# cslr_wdt register map
Vendor: Texas Instruments
Peripheral module from a debugger description file (folder C5517).
Address unit: 16 bits
Registers are 16-bit, read-write, reset 0x0 unless marked. A register's access mark holds for its fields unless they carry their own. Offsets are as the file gives them; lines under a group give offsets from that group; [hi:lo] are bit positions; {n}, {i} and the like mark numbered series; 'fields as' and 'values as' point back to an identical list; <NAME> marks a mode.

## WDT — The WDT controller is used to setup the internal timers. Each timer can be configured as a Watchdog or a General purpose timer.
0x00 WDKCKLK — unlocks the WD Kick Register
  [15:0] KICKLOK — Used to unlock the Watchdog Kick Register. A 2 word key sequence must be written to this register. The following keys must be written this order Key 1 = 0x5555 and Key 2 = 0xAAAA. When this is written the Kick register can now be started. When reading back the KICKLOK register, the value that is returned in bits [1:0] give the current state of the lock state machine where 00 = Waiting for Key 1; 01 = Waiting for key 2; 11 = unlocked.
0x02 WDKICK — resets the counter to the start value
  [15:0] KICK — A write to the kick register when it is unlocked causes the the watchdown counter to be reloaded with the value in the WD Start Value register and start counting down again. It does not matter what value is written. Reading the register returns the current value of the counter.
0x04 WDSVLR — unlocks the WD Start value register
  [15:0] STVALLOK — Used to unlock the Watchdog Start Value Register. A 2 word key sequence must be written to this register. The following keys must be written this order Key 1 = 0x6666 and Key 2 = 0xBBBB. When this is written the WD Start Value register can now be input. When reading back the STVALLOK register, the value that is returned in bits [1:0] give the current state of the lock state machine where 00 = Waiting for Key 1; 01 = Waiting for key 2; 11 = unlocked.
0x06 WDSVR — defines the start value for the WD counter
  [15:0] STRTVAL — The value written to this register is what is loaded into the WD counter when the kick register is written to. A read of this register will return the the Start Value for the counter.
0x08 WDENLOK — unlocks the WD enable register
  [15:0] ENLOK — Used to unlock the Watchdog Enable Register. A 3 word key sequence must be written to this register. The following keys must be written this order Key 1 = 0x7777, Key 2 = 0xCCCC, and Key 3 = 0xDDDD. When this is written the WD Enable register can now be input. When reading back the ENLOK register, the value that is returned in bits [1:0] give the current state of the lock state machine where 00 = Waiting for Key 1; 01 = Waiting for key 2; 10 = Waiting for Key 3; 11 = unlocked.
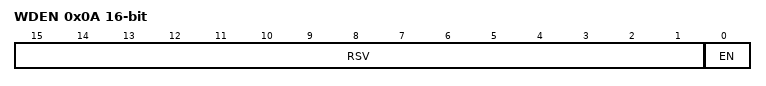
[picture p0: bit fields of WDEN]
0x0A WDEN — WD Enable/disable bit
  [15:1] RSV — Reserved
  [0] EN — used to enable/disable the WD timer. When enabled the counter begins counting down if the counter is allowed to reach 0 the chip will be reset.
    0=DISABLE (Watchdog Timer is disabled); 1=ENABLE (Watchdog Timer is enabled and begins counting down.)
0x0C WDPSLR — WD Enable/disable bit
  [15:0] PSLOK — Used to unlock the Watchdog Prescaler Register. A 2 word key sequence must be written to this register. The following keys must be written this order Key 1 = 0x5A5A and Key 2 = 0xA5A5. When this is written the WD Prescaler register can now be loaded. When reading back the PSLOK register, the value that is returned in bits [1:0] give the current state of the lock state machine where 00 = Waiting for Key 1; 01 = Waiting for key 2; 11 = unlocked.
0x0E WDPS — WD Enable/disable bit
  [15:0] PS — The WD Prescaler register stores the start value for the WD Prescaler. Each time the PS register counts down to 0 the WD counter is decremented by 1. A read will return the last value written to this register (the Prescaler start value)
